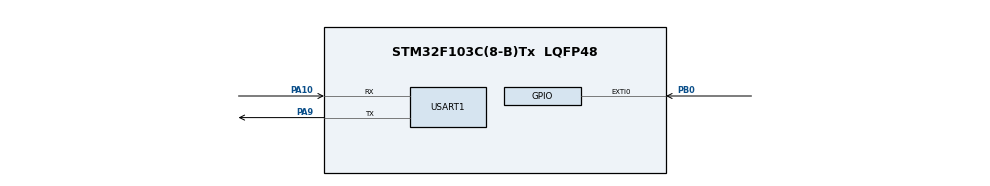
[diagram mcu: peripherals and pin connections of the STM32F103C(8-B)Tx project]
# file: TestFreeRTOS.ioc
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FREERTOS.Tasks01=defaultTask,0,128,StartDefaultTask,Default,NULL,Dynamic,NULL,NULL
Mcu.Family=STM32F1
Mcu.Name=STM32F103C(8-B)Tx
Mcu.Package=LQFP48
NVIC.EXTI0_IRQn=true\:5\:0\:false\:false\:true\:true\:true\:true\:true
NVIC.PriorityGroup=NVIC_PRIORITYGROUP_4
NVIC.TIM4_IRQn=true\:15\:0\:false\:false\:true\:false\:false\:true\:true
NVIC.TimeBase=TIM4_IRQn
NVIC.TimeBaseIP=TIM4
NVIC.USART1_IRQn=true\:5\:0\:false\:false\:true\:true\:true\:true\:true
PA10.Mode=Asynchronous
PA10.Signal=USART1_RX
PA13.Mode=Serial_Wire
PA13.Signal=SYS_JTMS-SWDIO
PA14.Mode=Serial_Wire
PA14.Signal=SYS_JTCK-SWCLK
PA9.Mode=Asynchronous
PA9.Signal=USART1_TX
PB0.GPIO_ModeDefaultEXTI=GPIO_MODE_IT_FALLING
PB0.GPIO_PuPd=GPIO_PULLUP
PB0.Signal=GPXTI0
ProjectManager.HeapSize=0x200
ProjectManager.StackSize=0x400
ProjectManager.TargetToolchain=MDK-ARM V5.32
RCC.APB1Freq_Value=8000000
RCC.APB2Freq_Value=8000000
USART1.VirtualMode=VM_ASYNC
VP_FREERTOS_VS_CMSIS_V1.Mode=CMSIS_V1
VP_SYS_VS_tim4.Mode=TIM4
board=custom

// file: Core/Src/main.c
/* USER CODE BEGIN Header */
/**
  ******************************************************************************
  * @file           : main.c
  * @brief          : Main program body
  ******************************************************************************
  * @attention
  *
  * Copyright (c) 2023 STMicroelectronics.
  * All rights reserved.
  *
  * This software is licensed under terms that can be found in the LICENSE file
  * in the root directory of this software component.
  * If no LICENSE file comes with this software, it is provided AS-IS.
  *
  ******************************************************************************
  */
/* USER CODE END Header */
#include "main.h"
#include "cmsis_os.h"

/* USER CODE BEGIN PTD */
uint8_t data1[1] = {49};
uint8_t data[1] = {48};
uint8_t data2[1] = {50};
volatile uint8_t t = 1;
uint8_t Rx;
/* USER CODE END PTD */

UART_HandleTypeDef huart1;

osThreadId defaultTaskHandle;
/* USER CODE BEGIN PV */
TaskHandle_t ScanIDTaskHandle;
TaskHandle_t CheckIDTaskHandle;
/* USER CODE END PV */

void SystemClock_Config(void);
static void MX_GPIO_Init(void);
static void MX_USART1_UART_Init(void);
void StartDefaultTask(void const * argument);

/* USER CODE BEGIN PFP */
void ScanIDTask(void *para);
void CheckIDTask(void *para);
/* USER CODE END PFP */

int main(void)
{

  /* MCU Configuration--------------------------------------------------------*/

  /* Reset of all peripherals, Initializes the Flash interface and the Systick. */
  HAL_Init();

  /* Configure the system clock */
  SystemClock_Config();

  /* Initialize all configured peripherals */
  MX_GPIO_Init();
  MX_USART1_UART_Init();
  /* USER CODE BEGIN 2 */
	HAL_UART_Receive_IT(&huart1, &Rx, 1);
  /* USER CODE END 2 */

  /* Create the thread(s) */
  /* definition and creation of defaultTask */
  osThreadDef(defaultTask, StartDefaultTask, osPriorityNormal, 0, 128);
  defaultTaskHandle = osThreadCreate(osThread(defaultTask), NULL);

  /* USER CODE BEGIN RTOS_THREADS */
  /* add threads, ... */
	xTaskCreate(ScanIDTask, "Task02", 624, NULL, osPriorityNormal, &ScanIDTaskHandle);
	xTaskCreate(CheckIDTask, "Task03", 128, NULL, osPriorityNormal, &CheckIDTaskHandle);
  /* USER CODE END RTOS_THREADS */

  /* Start scheduler */
  osKernelStart();

  /* We should never get here as control is now taken by the scheduler */
  /* Infinite loop */
  while (1)
  {

  }
}

void SystemClock_Config(void)
{
  RCC_OscInitTypeDef RCC_OscInitStruct = {0};
  RCC_ClkInitTypeDef RCC_ClkInitStruct = {0};

  /** Initializes the RCC Oscillators according to the specified parameters
  * in the RCC_OscInitTypeDef structure.
  */
  RCC_OscInitStruct.OscillatorType = RCC_OSCILLATORTYPE_HSI;
  RCC_OscInitStruct.HSIState = RCC_HSI_ON;
  RCC_OscInitStruct.HSICalibrationValue = RCC_HSICALIBRATION_DEFAULT;
  RCC_OscInitStruct.PLL.PLLState = RCC_PLL_NONE;
  if (HAL_RCC_OscConfig(&RCC_OscInitStruct) != HAL_OK)
  {
    Error_Handler();
  }

  /** Initializes the CPU, AHB and APB buses clocks
  */
  RCC_ClkInitStruct.ClockType = RCC_CLOCKTYPE_HCLK|RCC_CLOCKTYPE_SYSCLK
                              |RCC_CLOCKTYPE_PCLK1|RCC_CLOCKTYPE_PCLK2;
  RCC_ClkInitStruct.SYSCLKSource = RCC_SYSCLKSOURCE_HSI;
  RCC_ClkInitStruct.AHBCLKDivider = RCC_SYSCLK_DIV1;
  RCC_ClkInitStruct.APB1CLKDivider = RCC_HCLK_DIV1;
  RCC_ClkInitStruct.APB2CLKDivider = RCC_HCLK_DIV1;

  if (HAL_RCC_ClockConfig(&RCC_ClkInitStruct, FLASH_LATENCY_0) != HAL_OK)
  {
    Error_Handler();
  }
}

static void MX_USART1_UART_Init(void)
{

  huart1.Instance = USART1;
  huart1.Init.BaudRate = 115200;
  huart1.Init.WordLength = UART_WORDLENGTH_8B;
  huart1.Init.StopBits = UART_STOPBITS_1;
  huart1.Init.Parity = UART_PARITY_NONE;
  huart1.Init.Mode = UART_MODE_TX_RX;
  huart1.Init.HwFlowCtl = UART_HWCONTROL_NONE;
  huart1.Init.OverSampling = UART_OVERSAMPLING_16;
  if (HAL_UART_Init(&huart1) != HAL_OK)
  {
    Error_Handler();
  }

}

static void MX_GPIO_Init(void)
{
  GPIO_InitTypeDef GPIO_InitStruct = {0};

  /* GPIO Ports Clock Enable */
  __HAL_RCC_GPIOB_CLK_ENABLE();
  __HAL_RCC_GPIOA_CLK_ENABLE();

  /*Configure GPIO pin : PB0 */
  GPIO_InitStruct.Pin = GPIO_PIN_0;
  GPIO_InitStruct.Mode = GPIO_MODE_IT_FALLING;
  GPIO_InitStruct.Pull = GPIO_PULLUP;
  HAL_GPIO_Init(GPIOB, &GPIO_InitStruct);

  /* EXTI interrupt init*/
  HAL_NVIC_SetPriority(EXTI0_IRQn, 5, 0);
  HAL_NVIC_EnableIRQ(EXTI0_IRQn);

}

/* USER CODE BEGIN 4 */
void HAL_GPIO_EXTI_Callback(uint16_t GPIO_Pin)
{
		BaseType_t xHigherPriority;
		xHigherPriority = xTaskResumeFromISR(CheckIDTaskHandle);
		portEND_SWITCHING_ISR(xHigherPriority);
}
void HAL_UART_RxCpltCallback(UART_HandleTypeDef *huart)
{
	HAL_UART_Receive_IT(&huart1, &Rx, 1);
	if(Rx == 48)
		t = 0;
}
void ScanIDTask(void *para)
{

	while(1)
	{
		vTaskSuspend(NULL);
		HAL_UART_Transmit(&huart1, data, 1, 100);
		while(t == 1);
		t = 1;
		HAL_Delay(1000);
		vTaskResume(defaultTaskHandle);
	}
}
void CheckIDTask(void *para)
{

	while(1)
	{
		vTaskSuspend(NULL);
		HAL_UART_Transmit(&huart1, data2, 1, 100);
		HAL_Delay(1000);
		vTaskResume(ScanIDTaskHandle);
	}
}
/* USER CODE END 4 */

void StartDefaultTask(void const * argument)
{
  /* USER CODE BEGIN 5 */
  /* Infinite loop */
	while(1)
	{
		vTaskSuspend(NULL);
		HAL_UART_Transmit(&huart1, data1, 1, 100);
		HAL_Delay(1000);
		vTaskResume(CheckIDTaskHandle);
	}
  /* USER CODE END 5 */
}

void HAL_TIM_PeriodElapsedCallback(TIM_HandleTypeDef *htim)
{
  if (htim->Instance == TIM4) {
    HAL_IncTick();
  }
}

void Error_Handler(void)
{
  __disable_irq();
  while (1)
  {
  }
}
